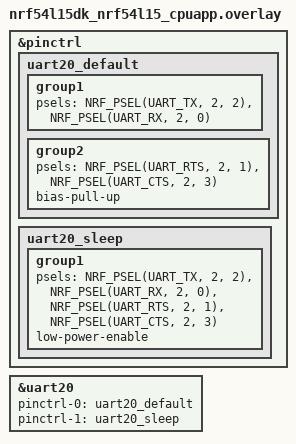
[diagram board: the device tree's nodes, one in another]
&pinctrl {
    uart20_default: uart20_default {
        group1 {
            psels = <NRF_PSEL(UART_TX, 2, 2)>,
                    <NRF_PSEL(UART_RX, 2, 0)>;
        };
        group2 {
            psels = <NRF_PSEL(UART_RTS, 2, 1)>,
                    <NRF_PSEL(UART_CTS, 2, 3)>;
            bias-pull-up;
        };
    };

    uart20_sleep: uart20_sleep {
        group1 {
            psels = <NRF_PSEL(UART_TX, 2, 2)>,
                    <NRF_PSEL(UART_RX, 2, 0)>,
                    <NRF_PSEL(UART_RTS, 2, 1)>,
                    <NRF_PSEL(UART_CTS, 2, 3)>;
            low-power-enable;
        };
    };
};

&uart20 {
    status = "okay";
    pinctrl-0 = <&uart20_default>;
    pinctrl-1 = <&uart20_sleep>;
    pinctrl-names = "default", "sleep";
};
